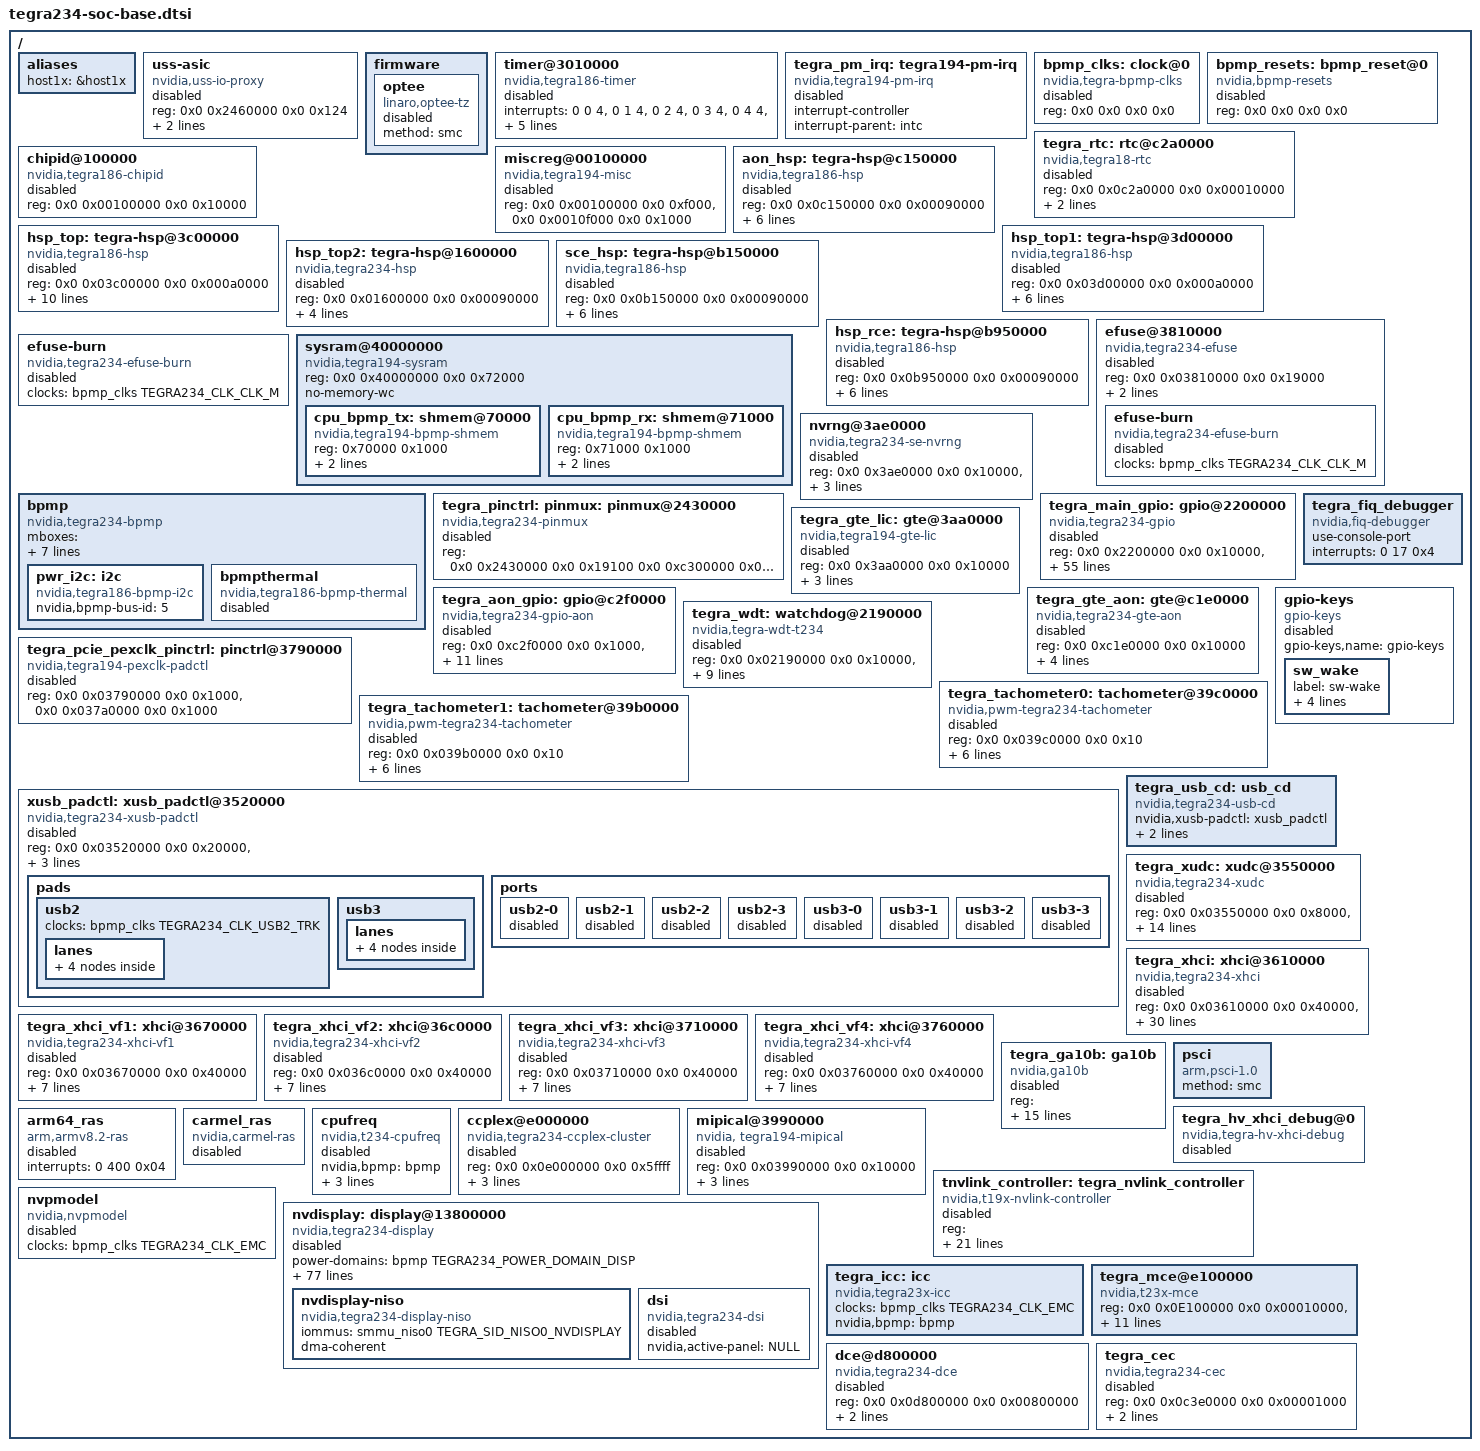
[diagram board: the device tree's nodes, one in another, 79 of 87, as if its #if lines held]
/*
 * Copyright (c) 2014-2023, NVIDIA CORPORATION.  All rights reserved.
 *
 * This program is free software; you can redistribute it and/or modify it
 * under the terms and conditions of the GNU General Public License,
 * version 2, as published by the Free Software Foundation.
 *
 * This program is distributed in the hope it will be useful, but WITHOUT
 * ANY WARRANTY; without even the implied warranty of MERCHANTABILITY or
 * FITNESS FOR A PARTICULAR PURPOSE.  See the GNU General Public License for
 * more details.
 *
 * You should have received a copy of the GNU General Public License
 * along with this program.  If not, see <http://www.gnu.org/licenses/>.
 */

/* FIXME: remove all the tegra194-*** headers */
#include <dt-bindings/version.h>
#include <dt-bindings/clock/tegra234-clock.h>
#include <dt-bindings/reset/tegra234-reset.h>
#include <dt-bindings/interrupt/tegra234-irq.h>
#include "dt-bindings/interrupt-controller/arm-gic.h"
#include "dt-bindings/soc/tegra234-powergate.h"
#include <dt-bindings/interrupt-controller/irq.h>
#include <dt-bindings/gpio/tegra234-gpio.h>
#include <dt-bindings/pinctrl/pinctrl-tegra.h>
#include <dt-bindings/mailbox/tegra186-hsp.h>
/* Minimal.dtsi is to be included first as subsequent headers can
 *override the nodes.
 */
#include "tegra234-soc/tegra234-soc-minimal.dtsi"
#include "tegra234-soc-memory.dtsi"
#include "tegra234-trusty.dtsi"
#include "tegra234-soc-cbb.dtsi"
#include "tegra234-soc-pcie.dtsi"
#include "tegra234-soc-eqos.dtsi"
#include "tegra234-soc-mgbe.dtsi"
#include "tegra234-soc-uart.dtsi"
#include "tegra234-soc-sdhci.dtsi"
#include "tegra234-soc-ufshc.dtsi"
#include "tegra234-soc-spi.dtsi"
#include "tegra234-soc-pwm.dtsi"
#include "tegra234-soc-i2c.dtsi"
#include "tegra234-soc-gpcdma.dtsi"
#include "tegra234-soc-can.dtsi"
#include "tegra234-soc-audio.dtsi"
#include "tegra234-safety-sce.dtsi"
#include "tegra234-camera.dtsi"
#include "tegra234-soc/tegra234-soc-actmon.dtsi"
#include "tegra234-soc/tegra234-aon.dtsi"
#include "tegra234-soc/tegra234-cpus.dtsi"
#include "tegra234-soc-thermal.dtsi"
#include "tegra234-soc-ldpc.dtsi"
#include "tegra234-soc/tegra234-psc.dtsi"
#include "dt-bindings/soc/tegra-io-pads.h"
#include "dt-bindings/input/input.h"
#include "tegra234-soc-pmc.dtsi"
#include "tegra234-soc-host1x.dtsi"
#include "tegra234-soc-mods.dtsi"
#include <dt-bindings/interconnect/tegra_icc_id.h>

#include "tegra234-soc/tegra234-automotive-nvguard.dtsi"
#include "tegra234-soc/tegra234-automotive-nvguard-srvprop.dtsi"

#include "tegra234-soc-coresight.dtsi"
#include "tegra234-soc-fsicom.dtsi"
#include "tegra234-safetyservice.dtsi"

/ {
	aliases {
		host1x = &host1x;
	};

	uss-asic {
		compatible = "nvidia,uss-io-proxy";
		reg = <0x0 0x2460000 0x0 0x124>;
		clocks = <&bpmp_clks TEGRA234_CLK_I2S8>;
		clock-names = "i2s8";
		resets = <&bpmp_resets TEGRA234_RESET_I2S8>;
		reset-names = "i2s8";
		status = "disabled";
	};

	firmware {
		optee {
			compatible = "linaro,optee-tz";
			method = "smc";
			status = "disabled";
		};
	};

	timer@3010000 {
		/* Do not enable this node (SOC Timer) as ARM Generic Timer
		 * (DT node="timer") should be used instead
		 */
		compatible = "nvidia,tegra186-timer";
		interrupts = <0 0 4>,
			     <0 1 4>,
			     <0 2 4>,
			     <0 3 4>,
			     <0 4 4>,
			     <0 5 4>,
			     <0 6 4>,
			     <0 7 4>;
		clock-frequency = <19200000>;
		reg = <0x0 0x03010000 0x0 0x000e0000>;
		tmr-count = <10>;
		wdt-count = <3>;
		status = "disabled";
	};

	tegra_pm_irq: tegra194-pm-irq {
		compatible = "nvidia,tegra194-pm-irq";
		interrupt-controller;
		#interrupt-cells = <3>;
		interrupt-parent = <&intc>;
		status = "disabled";
	};

#if TEGRA_BPMP_FW_DT_VERSION <= DT_VERSION_1
	bpmp_clks: clock@0 {
		compatible = "nvidia,tegra-bpmp-clks";
		reg = <0x0 0x0 0x0 0x0>;
		#clock-cells = <1>;
		status = "disabled";
	};

	bpmp_resets: bpmp_reset@0 {
		compatible = "nvidia,bpmp-resets";
		reg = <0x0 0x0 0x0 0x0>;
		#reset-cells = <1>;
		status = "disabled";
	};
#endif

	tegra_rtc: rtc@c2a0000 {
		compatible = "nvidia,tegra18-rtc";
		reg = <0x0 0x0c2a0000 0x0 0x00010000>;
		interrupt-parent = <&tegra_pmc>;
		interrupts = <73 IRQ_TYPE_LEVEL_HIGH>;
		status = "disabled";
	};

	chipid@100000 {
		compatible = "nvidia,tegra186-chipid";
		reg = <0x0 0x00100000 0x0 0x10000>;
		status = "disabled";
	};

	miscreg@00100000 {
		compatible = "nvidia,tegra194-misc", "nvidia,tegra186-miscreg";
		reg = <0x0 0x00100000 0x0 0xf000>, /* Chipid */
		    <0x0 0x0010f000 0x0 0x1000>; /* Straps */
		status = "disabled";
	};

	aon_hsp: tegra-hsp@c150000 {
		compatible = "nvidia,tegra186-hsp";
		reg = <0x0 0x0c150000 0x0 0x00090000>;
		interrupts =	<0 TEGRA234_IRQ_AON_HSP_SHARED_1 0x4>,
				<0 TEGRA234_IRQ_AON_HSP_SHARED_2 0x4>,
				<0 TEGRA234_IRQ_AON_HSP_SHARED_3 0x4>,
				<0 TEGRA234_IRQ_AON_HSP_SHARED_4 0x4>;
		interrupt-names = "shared1", "shared2", "shared3", "shared4";
		#mbox-cells = <2>;
		nvidia,mbox-ie;
		status = "disabled";
	};

	hsp_top: tegra-hsp@3c00000 {
		compatible = "nvidia,tegra186-hsp";
		reg = <0x0 0x03c00000 0x0 0x000a0000>;
		interrupts =	<0 176 0x4>,
				<0 TEGRA234_IRQ_TOP0_HSP_SHARED_0 0x4>,
				<0 TEGRA234_IRQ_TOP0_HSP_SHARED_1 0x4>,
				<0 TEGRA234_IRQ_TOP0_HSP_SHARED_2 0x4>,
				<0 TEGRA234_IRQ_TOP0_HSP_SHARED_3 0x4>,
				<0 TEGRA234_IRQ_TOP0_HSP_SHARED_4 0x4>,
				<0 TEGRA234_IRQ_TOP0_HSP_SHARED_5 0x4>,
				<0 TEGRA234_IRQ_TOP0_HSP_SHARED_6 0x4>,
				<0 TEGRA234_IRQ_TOP0_HSP_SHARED_7 0x4>;
		interrupt-names = "doorbell",
				"shared0", "shared1", "shared2", "shared3",
				"shared4", "shared5", "shared6", "shared7";
		#mbox-cells = <2>;
		nvidia,mbox-ie;
		status = "disabled";
	};

	hsp_top1: tegra-hsp@3d00000 {
		compatible = "nvidia,tegra186-hsp";
		reg = <0x0 0x03d00000 0x0 0x000a0000>;
		interrupts = <0 TEGRA234_IRQ_TOP1_HSP_SHARED_0 0x4>,
				<0 TEGRA234_IRQ_TOP1_HSP_SHARED_1 0x4>,
				<0 TEGRA234_IRQ_TOP1_HSP_SHARED_2 0x4>,
				<0 TEGRA234_IRQ_TOP1_HSP_SHARED_3 0x4>,
				<0 TEGRA234_IRQ_TOP1_HSP_SHARED_4 0x4>;
		interrupt-names = "shared0", "shared1", "shared2", "shared3", "shared4";
		#mbox-cells = <2>;
		status = "disabled";
	};

	hsp_top2: tegra-hsp@1600000 {
		compatible = "nvidia,tegra234-hsp","nvidia,tegra186-hsp";
		reg = <0x0 0x01600000 0x0 0x00090000>;
		interrupts = <0 265 0x4>, <0 266 0x4>, <0 267 0x4>,
        <0 268 0x4>, <0 269 0x4>, <0 270 0x4>, <0 271 0x4>, <0 272 0x4>;
		interrupt-names = "shared0", "shared1", "shared2", "shared3",
				"shared4", "shared5", "shared6", "shared7";
		#mbox-cells = <2>;
		nvidia,mbox-ie;
		status = "disabled";
	};




	sce_hsp: tegra-hsp@b150000 {
		compatible = "nvidia,tegra186-hsp";
		reg = <0x0 0x0b150000 0x0 0x00090000>;
		interrupts =	<0 TEGRA234_IRQ_SCE_HSP_SHARED_1 0x4>,
				<0 TEGRA234_IRQ_SCE_HSP_SHARED_2 0x4>,
				<0 TEGRA234_IRQ_SCE_HSP_SHARED_3 0x4>,
				<0 TEGRA234_IRQ_SCE_HSP_SHARED_4 0x4>;
		interrupt-names = "shared1", "shared2", "shared3", "shared4";
		nvidia,mbox-ie;
		status = "disabled";
	};

	hsp_rce: tegra-hsp@b950000 {
		compatible = "nvidia,tegra186-hsp";
		reg = <0x0 0x0b950000 0x0 0x00090000>;
		interrupts =	<0 TEGRA234_IRQ_RCE_HSP_SHARED_1 0x4>,
				<0 TEGRA234_IRQ_RCE_HSP_SHARED_2 0x4>,
				<0 TEGRA234_IRQ_RCE_HSP_SHARED_3 0x4>,
				<0 TEGRA234_IRQ_RCE_HSP_SHARED_4 0x4>;
		nvidia,mbox-ie;
		#mbox-cells = <2>;
		interrupt-names = "shared1", "shared2", "shared3", "shared4";
		status = "disabled";
	};

	efuse@3810000 {
		compatible = "nvidia,tegra234-efuse";
		reg = <0x0 0x03810000 0x0 0x19000>;
		clocks = <&bpmp_clks TEGRA234_CLK_FUSE>,
		         <&bpmp_clks TEGRA234_CLK_CLK_M>;
		clock-names = "fuse", "clk_m";
		status = "disabled";
#if LINUX_VERSION < 419
		efuse-burn {
			compatible = "nvidia,tegra234-efuse-burn";
			clocks = <&bpmp_clks TEGRA234_CLK_CLK_M>;
			clock-names = "clk_m";
			status = "disabled";
		};
#endif
	};

#if LINUX_VERSION >= 419
	efuse-burn {
		compatible = "nvidia,tegra234-efuse-burn";
		clocks = <&bpmp_clks TEGRA234_CLK_CLK_M>;
		clock-names = "clk_m";
		status = "disabled";
	};
#endif

#if TEGRA_BPMP_FW_DT_VERSION >= DT_VERSION_2
	sysram@40000000 {
		compatible = "nvidia,tegra194-sysram", "mmio-sram";
		reg = <0x0 0x40000000 0x0 0x72000>;
		#address-cells = <1>;
		#size-cells = <1>;
		ranges = <0x0 0x0 0x40000000 0x72000>;
		no-memory-wc;

		cpu_bpmp_tx: shmem@70000 {
			compatible = "nvidia,tegra194-bpmp-shmem";
			reg = <0x70000 0x1000>;
			label = "cpu-bpmp-tx";
			pool;
		};

		cpu_bpmp_rx: shmem@71000 {
			compatible = "nvidia,tegra194-bpmp-shmem";
			reg = <0x71000 0x1000>;
			label = "cpu-bpmp-rx";
			pool;
		};
	};

	bpmp: bpmp {
		compatible = "nvidia,tegra234-bpmp", "nvidia,tegra186-bpmp";
		mboxes = <&hsp_top TEGRA_HSP_MBOX_TYPE_DB
				   TEGRA_HSP_DB_MASTER_BPMP>;
		shmem = <&cpu_bpmp_tx &cpu_bpmp_rx>;
		#clock-cells = <1>;
		#reset-cells = <1>;
		#power-domain-cells = <1>;
#if TEGRA_IOMMU_DT_VERSION >= DT_VERSION_2
		interconnects = <&mc TEGRA234_MEMORY_CLIENT_BPMPR>,
				<&mc TEGRA234_MEMORY_CLIENT_BPMPW>,
				<&mc TEGRA234_MEMORY_CLIENT_BPMPDMAR>,
				<&mc TEGRA234_MEMORY_CLIENT_BPMPDMAW>;
		interconnect-names = "dma-mem", "dma-mem", "dma-mem", "dma-mem";
#endif

		pwr_i2c: i2c {
			compatible = "nvidia,tegra186-bpmp-i2c";
			nvidia,bpmp-bus-id = <5>;
			#address-cells = <1>;
			#size-cells = <0>;
		};

		bpmpthermal {
			compatible = "nvidia,tegra186-bpmp-thermal";
			#thermal-sensor-cells = <1>;
			status = "disabled";
		};
	};
#else
	bpmp: bpmp {
		compatible = "nvidia,tegra186-bpmp";
		iommus = <&smmu_niso1 TEGRA_SID_NISO1_BPMP>;
		dma-coherent;
		reg = <0x0 0x0d000000 0x0 0x00800000>,
		      <0x0 0x40070000 0x0 0x00001000>,
		      <0x0 0x40071000 0x0 0x00001000>;
		status = "disabled";
		#power-domain-cells = <1>;
		#strap-cells = <1>;
		#nvidia,controller-id-cells = <1>;

		bpmpthermal {
			compatible = "nvidia,tegra186-bpmp-thermal";
			#thermal-sensor-cells = <1>;
			status = "disabled";
		};
	};
#endif

	nvrng@3ae0000 {
		compatible = "nvidia,tegra234-se-nvrng";
		reg-names = "rng1", "sap";
		reg = <0x0 0x3ae0000 0x0 0x10000>,
		      <0x0 0x3ac0000 0x0 0x10000>;
		interrupts = <0x0 284 0x4>;
		clocks = <&bpmp_clks TEGRA234_CLK_SE>;
		clock-names = "se";
		status = "disabled";
	};

	tegra_pinctrl: pinmux: pinmux@2430000 {
		compatible = "nvidia,tegra234-pinmux";
		reg = <0x0 0x2430000 0x0 0x19100
			0x0 0xc300000 0x0 0x4000>;
		#gpio-range-cells = <3>;
		status = "disabled";
};

	tegra_main_gpio: gpio@2200000 {
		compatible = "nvidia,tegra234-gpio";
		reg-names = "security", "gpio";
		reg =
			<0x0 0x2200000 0x0 0x10000>,
			<0x0 0x2210000 0x0 0x10000>;
		interrupts =
			<0 TEGRA234_IRQ_GPIO0_0 IRQ_TYPE_LEVEL_HIGH>,
			<0 TEGRA234_IRQ_GPIO0_1 IRQ_TYPE_LEVEL_HIGH>,
			<0 TEGRA234_IRQ_GPIO0_2 IRQ_TYPE_LEVEL_HIGH>,
			<0 TEGRA234_IRQ_GPIO0_3 IRQ_TYPE_LEVEL_HIGH>,
			<0 TEGRA234_IRQ_GPIO0_4 IRQ_TYPE_LEVEL_HIGH>,
			<0 TEGRA234_IRQ_GPIO0_5 IRQ_TYPE_LEVEL_HIGH>,
			<0 TEGRA234_IRQ_GPIO0_6 IRQ_TYPE_LEVEL_HIGH>,
			<0 TEGRA234_IRQ_GPIO0_7 IRQ_TYPE_LEVEL_HIGH>,
			<0 TEGRA234_IRQ_GPIO1_0 IRQ_TYPE_LEVEL_HIGH>,
			<0 TEGRA234_IRQ_GPIO1_1 IRQ_TYPE_LEVEL_HIGH>,
			<0 TEGRA234_IRQ_GPIO1_2 IRQ_TYPE_LEVEL_HIGH>,
			<0 TEGRA234_IRQ_GPIO1_3 IRQ_TYPE_LEVEL_HIGH>,
			<0 TEGRA234_IRQ_GPIO1_4 IRQ_TYPE_LEVEL_HIGH>,
			<0 TEGRA234_IRQ_GPIO1_5 IRQ_TYPE_LEVEL_HIGH>,
			<0 TEGRA234_IRQ_GPIO1_6 IRQ_TYPE_LEVEL_HIGH>,
			<0 TEGRA234_IRQ_GPIO1_7 IRQ_TYPE_LEVEL_HIGH>,
			<0 TEGRA234_IRQ_GPIO2_0 IRQ_TYPE_LEVEL_HIGH>,
			<0 TEGRA234_IRQ_GPIO2_1 IRQ_TYPE_LEVEL_HIGH>,
			<0 TEGRA234_IRQ_GPIO2_2 IRQ_TYPE_LEVEL_HIGH>,
			<0 TEGRA234_IRQ_GPIO2_3 IRQ_TYPE_LEVEL_HIGH>,
			<0 TEGRA234_IRQ_GPIO2_4 IRQ_TYPE_LEVEL_HIGH>,
			<0 TEGRA234_IRQ_GPIO2_5 IRQ_TYPE_LEVEL_HIGH>,
			<0 TEGRA234_IRQ_GPIO2_6 IRQ_TYPE_LEVEL_HIGH>,
			<0 TEGRA234_IRQ_GPIO2_7 IRQ_TYPE_LEVEL_HIGH>,
			<0 TEGRA234_IRQ_GPIO3_0 IRQ_TYPE_LEVEL_HIGH>,
			<0 TEGRA234_IRQ_GPIO3_1 IRQ_TYPE_LEVEL_HIGH>,
			<0 TEGRA234_IRQ_GPIO3_2 IRQ_TYPE_LEVEL_HIGH>,
			<0 TEGRA234_IRQ_GPIO3_3 IRQ_TYPE_LEVEL_HIGH>,
			<0 TEGRA234_IRQ_GPIO3_4 IRQ_TYPE_LEVEL_HIGH>,
			<0 TEGRA234_IRQ_GPIO3_5 IRQ_TYPE_LEVEL_HIGH>,
			<0 TEGRA234_IRQ_GPIO3_6 IRQ_TYPE_LEVEL_HIGH>,
			<0 TEGRA234_IRQ_GPIO3_7 IRQ_TYPE_LEVEL_HIGH>,
			<0 TEGRA234_IRQ_GPIO4_0 IRQ_TYPE_LEVEL_HIGH>,
			<0 TEGRA234_IRQ_GPIO4_1 IRQ_TYPE_LEVEL_HIGH>,
			<0 TEGRA234_IRQ_GPIO4_2 IRQ_TYPE_LEVEL_HIGH>,
			<0 TEGRA234_IRQ_GPIO4_3 IRQ_TYPE_LEVEL_HIGH>,
			<0 TEGRA234_IRQ_GPIO4_4 IRQ_TYPE_LEVEL_HIGH>,
			<0 TEGRA234_IRQ_GPIO4_5 IRQ_TYPE_LEVEL_HIGH>,
			<0 TEGRA234_IRQ_GPIO4_6 IRQ_TYPE_LEVEL_HIGH>,
			<0 TEGRA234_IRQ_GPIO4_7 IRQ_TYPE_LEVEL_HIGH>,
			<0 TEGRA234_IRQ_GPIO5_0 IRQ_TYPE_LEVEL_HIGH>,
			<0 TEGRA234_IRQ_GPIO5_1 IRQ_TYPE_LEVEL_HIGH>,
			<0 TEGRA234_IRQ_GPIO5_2 IRQ_TYPE_LEVEL_HIGH>,
			<0 TEGRA234_IRQ_GPIO5_3 IRQ_TYPE_LEVEL_HIGH>,
			<0 TEGRA234_IRQ_GPIO5_4 IRQ_TYPE_LEVEL_HIGH>,
			<0 TEGRA234_IRQ_GPIO5_5 IRQ_TYPE_LEVEL_HIGH>,
			<0 TEGRA234_IRQ_GPIO5_6 IRQ_TYPE_LEVEL_HIGH>,
			<0 TEGRA234_IRQ_GPIO5_7 IRQ_TYPE_LEVEL_HIGH>;
		gpio-controller;
		#gpio-cells = <2>;
		interrupt-controller;
		#interrupt-cells = <2>;
		gpio-ranges =
			<&tegra_pinctrl TEGRA234_MAIN_GPIO_OFFSET TEGRA234_MAIN_PINCTRL_OFFSET_A TEGRA234_MAIN_PINS_A_TO_Z>,
			<&tegra_pinctrl TEGRA234_MAIN_PINS_A_TO_Z TEGRA234_MAIN_PINCTRL_OFFSET_AC TEGRA234_MAIN_PINS_AC_TO_AG>;
		status = "disabled";
	};

	tegra_aon_gpio: gpio@c2f0000 {
		compatible = "nvidia,tegra234-gpio-aon";
		reg-names = "security", "gpio";
		reg = 	<0x0 0xc2f0000 0x0 0x1000>,
			<0x0 0xc2f1000 0x0 0x1000>;
		interrupts =
			<0 TEGRA234_IRQ_AON_GPIO_0 IRQ_TYPE_LEVEL_HIGH>,
			<0 TEGRA234_IRQ_AON_GPIO_1 IRQ_TYPE_LEVEL_HIGH>,
			<0 TEGRA234_IRQ_AON_GPIO_2 IRQ_TYPE_LEVEL_HIGH>,
			<0 TEGRA234_IRQ_AON_GPIO_3 IRQ_TYPE_LEVEL_HIGH>;
		gpio-controller;
		#gpio-cells = <2>;
		interrupt-controller;
		#interrupt-cells = <2>;
		gpio-ranges =
			<&tegra_pinctrl TEGRA234_MAIN_GPIO_OFFSET TEGRA234_MAIN_PINS_A_TO_Z TEGRA234_AON_PINS_AA>,
			<&tegra_pinctrl TEGRA234_AON_PINS_AA TEGRA234_AON_PINCTRL_OFFSET_BB TEGRA234_AON_PINS_BB_TO_GG>;
		status = "disabled";
	};

	tegra_gte_lic: gte@3aa0000 {
                compatible = "nvidia,tegra194-gte-lic";
                reg = <0x0 0x3aa0000 0x0 0x10000>;
                interrupts = <0 11 0x4>;
                nvidia,int-threshold = <1>;
                nvidia,num-slices = <17>;
                status = "disabled";
        };

        tegra_gte_aon: gte@c1e0000 {
                compatible = "nvidia,tegra234-gte-aon";
                reg = <0x0 0xc1e0000 0x0 0x10000>;
                interrupts = <0 13 0x4>;
                nvidia,int-threshold = <1>;
                nvidia,num-slices = <3>;
                nvidia,gpio-controller = <&tegra_aon_gpio>;
                status = "disabled";
        };

	tegra_wdt: watchdog@2190000 {
		compatible = "nvidia,tegra-wdt-t234";
		reg = <0x0 0x02190000 0x0 0x10000>, /* WDT0 */
		      <0x0 0x02090000 0x0 0x10000>, /* TMR0 */
		      <0x0 0x02080000 0x0 0x10000>; /* TKE */
		interrupts = <0 7 0x4 0 8 0x4>; /* TKE shared int */
		nvidia,watchdog-index = <0>;
		nvidia,timer-index = <7>;
		nvidia,enable-on-init;
		nvidia,extend-watchdog-suspend;
		timeout-sec = <120>;
		nvidia,disable-debug-reset;
		status = "disabled";
	};

	tegra_fiq_debugger {
		compatible = "nvidia,fiq-debugger";
		use-console-port;
		interrupts = <0 17 0x4>;
	};

	tegra_pcie_pexclk_pinctrl: pinctrl@3790000 {
		compatible = "nvidia,tegra194-pexclk-padctl";
		reg = <0x0 0x03790000 0x0 0x1000>,
		      <0x0 0x037a0000 0x0 0x1000>;
		status = "disabled";
	};

	tegra_tachometer0: tachometer@39c0000 {
		compatible = "nvidia,pwm-tegra234-tachometer";
		reg = <0x0 0x039c0000 0x0 0x10>;
		#pwm-cells = <2>;
		clocks = <&bpmp_clks TEGRA234_CLK_TACH0>;
		clock-names = "tach";
		resets = <&bpmp_resets TEGRA234_RESET_TACH0>;
		reset-names = "tach";
		interrupts = <0 TEGRA234_IRQ_TACH0 0x4>;
		pulse-per-rev = <2>;
		capture-window-length = <2>;
		disable-clk-gate;
		status = "disabled";
	};

	tegra_tachometer1: tachometer@39b0000 {
		compatible = "nvidia,pwm-tegra234-tachometer";
		reg = <0x0 0x039b0000 0x0 0x10>;
		#pwm-cells = <2>;
		clocks = <&bpmp_clks TEGRA234_CLK_TACH1>;
		clock-names = "tach";
		resets = <&bpmp_resets TEGRA234_RESET_TACH1>;
		reset-names = "tach";
		interrupts = <0 TEGRA234_IRQ_TACH1 0x4>;
		pulse-per-rev = <2>;
		capture-window-length = <2>;
		disable-clk-gate;
		status = "disabled";
	};

	gpio-keys {
		compatible = "gpio-keys";
		gpio-keys,name = "gpio-keys";
		status = "disabled";

		sw_wake {
			label = "sw-wake";
			linux,code = <KEY_WAKEUP>;
			wakeup-source;
			interrupt-parent = <&tegra_pmc>;
			interrupts = <83 IRQ_TYPE_EDGE_RISING>;
		};
	};

	xusb_padctl: xusb_padctl@3520000 {
		compatible = "nvidia,tegra234-xusb-padctl";
		reg = <0x0 0x03520000 0x0 0x20000>,
			<0x0 0x03540000 0x0 0x10000>;
		reg-names = "padctl", "ao";
		interrupts = <0 167 0x4>;
		resets = <&bpmp_resets TEGRA234_RESET_XUSB_PADCTL>;
		reset-names = "padctl";
		status = "disabled";

		pads {
			usb2 {
				clocks = <&bpmp_clks TEGRA234_CLK_USB2_TRK>;
				clock-names = "trk";

				lanes {
					usb2-0 {
						status = "disabled";
						#phy-cells = <0>;
					};
					usb2-1 {
						status = "disabled";
						#phy-cells = <0>;
					};
					usb2-2 {
						status = "disabled";
						#phy-cells = <0>;
					};
					usb2-3 {
						status = "disabled";
						#phy-cells = <0>;
					};
				};
			};
			usb3 {
				lanes {
					usb3-0 {
						status = "disabled";
						#phy-cells = <0>;
					};
					usb3-1 {
						status = "disabled";
						#phy-cells = <0>;
					};
					usb3-2 {
						status = "disabled";
						#phy-cells = <0>;
					};
					usb3-3 {
						status = "disabled";
						#phy-cells = <0>;
					};
				};
			};
		};

		ports {
			usb2-0 {
				status = "disabled";
			};
			usb2-1 {
				status = "disabled";
			};
			usb2-2 {
				status = "disabled";
			};
			usb2-3 {
				status = "disabled";
			};
			usb3-0 {
				status = "disabled";
			};
			usb3-1 {
				status = "disabled";
			};
			usb3-2 {
				status = "disabled";
			};
			usb3-3 {
				status = "disabled";
			};
		};
	};

	tegra_usb_cd: usb_cd {
		compatible = "nvidia,tegra234-usb-cd";
		nvidia,xusb-padctl = <&xusb_padctl>;
		phys = <&{/xusb_padctl@3520000/pads/usb2/lanes/usb2-0}>;
		phy-names = "otg-phy";
		status = "okay";
	};

	tegra_xudc: xudc@3550000 {
		compatible = "nvidia,tegra234-xudc";
		reg = <0x0 0x03550000 0x0 0x8000>,
			<0x0 0x03558000 0x0 0x8000>;
		reg-names = "base", "fpci";
		interrupts = <0 166 0x4>;
		clocks = <&bpmp_clks TEGRA234_CLK_XUSB_CORE_DEV>,
			<&bpmp_clks TEGRA234_CLK_XUSB_SS_SUPERSPEED>,
			<&bpmp_clks TEGRA234_CLK_XUSB_SS>,
			<&bpmp_clks TEGRA234_CLK_XUSB_FS>;
		clock-names = "dev", "ss", "ss_src", "fs_src";

#if defined(LINUX_VERSION) && LINUX_VERSION > 414
                power-domains =  <&bpmp TEGRA234_POWER_DOMAIN_XUSBB>,
                        <&bpmp TEGRA234_POWER_DOMAIN_XUSBA>,
                        <&bpmp TEGRA234_POWER_DOMAIN_XUSBC>;
                power-domain-names = "dev", "ss", "host";
#endif

		nvidia,xusb-padctl = <&xusb_padctl>;

		iommus = <&smmu_niso1 TEGRA_SID_NISO1_XUSB_DEV>;
		dma-coherent;

		status = "disabled";
		charger-detector = <&tegra_usb_cd>;
	};

	tegra_xhci: xhci@3610000 {
		compatible = "nvidia,tegra234-xhci", "nvidia,tegra234-xusb";
		reg = <0x0 0x03610000 0x0 0x40000>,
			<0x0 0x03600000 0x0 0x10000>,
			<0x0 0x03650000 0x0 0x10000>;
		reg-names = "base", "fpci", "bar2";
		interrupts-extended = <&intc 0 163 0x4>,
				      <&intc 0 164 0x4>,
				      <&intc 0 167 0x4>,
				      <&tegra_pmc 76 0x4>,
				      <&tegra_pmc 77 0x4>,
				      <&tegra_pmc 78 0x4>,
				      <&tegra_pmc 79 0x4>,
				      <&tegra_pmc 80 0x4>,
				      <&tegra_pmc 81 0x4>,
				      <&tegra_pmc 82 0x4>;
		/*
                   wake0, wake1, wake2 are for USB3.0 ports
                   wake3, wake4, wake5, wake6 are for USB2.0 ports
		*/
		interrupt-names = "xhci", "mbox", "padctl",
				  "wake0", "wake1", "wake2", "wake3",
				  "wake4", "wake5", "wake6";

		clocks = <&bpmp_clks TEGRA234_CLK_XUSB_CORE_MUX>,
			<&bpmp_clks TEGRA234_CLK_XUSB_CORE_HOST>,
			<&bpmp_clks TEGRA234_CLK_XUSB_CORE_SS>,
			<&bpmp_clks TEGRA234_CLK_XUSB_FALCON>,
			<&bpmp_clks TEGRA234_CLK_XUSB_FALCON_HOST>,
			<&bpmp_clks TEGRA234_CLK_XUSB_FALCON_SS>,
			<&bpmp_clks TEGRA234_CLK_XUSB_FS>,
			<&bpmp_clks TEGRA234_CLK_XUSB_FS_HOST>,
			<&bpmp_clks TEGRA234_CLK_XUSB_SS>,
			<&bpmp_clks TEGRA234_CLK_XUSB_SS_SUPERSPEED>,
			<&bpmp_clks TEGRA234_CLK_UTMIP_PLL>,
			<&bpmp_clks TEGRA234_CLK_CLK_M>,
			<&bpmp_clks TEGRA234_CLK_PLLE>;
		clock-names = "xusb_hs_src", "xusb_host",
			"xusb_core_superspeed_clk", "xusb_falcon_src",
			"xusb_falcon_host_clk", "xusb_falcon_superspeed_clk",
			"xusb_fs_src", "xusb_fs_host_clk", "xusb_ss_src",
			"xusb_ss", "pll_u_480m", "clk_m", "pll_e";

#if defined(LINUX_VERSION) && LINUX_VERSION > 414
		power-domains =  <&bpmp TEGRA234_POWER_DOMAIN_XUSBC>,
			<&bpmp TEGRA234_POWER_DOMAIN_XUSBA>;
		power-domain-names = "xusb_host", "xusb_ss";
#endif

		nvidia,xusb-padctl = <&xusb_padctl>;

#if TEGRA_IOMMU_DT_VERSION >= DT_VERSION_2
		interconnects = <&mc TEGRA234_MEMORY_CLIENT_XUSB_HOSTR>,
				<&mc TEGRA234_MEMORY_CLIENT_XUSB_HOSTW>;
		interconnect-names = "dma-mem", "dma-mem";
#endif
		iommus = <&smmu_niso1 TEGRA_SID_NISO1_XUSB_HOST>;
		dma-coherent;

		status = "disabled";
	};

	tegra_xhci_vf1: xhci@3670000 {
		compatible = "nvidia,tegra234-xhci-vf1";
		reg = <0x0 0x03670000 0x0 0x40000>;
		interrupts = <0 21 0x4>;

		nvidia,xusb-padctl = <&xusb_padctl>;

#if TEGRA_IOMMU_DT_VERSION >= DT_VERSION_2
		interconnects = <&mc TEGRA234_MEMORY_CLIENT_XUSB_HOSTR>,
				<&mc TEGRA234_MEMORY_CLIENT_XUSB_HOSTW>;
		interconnect-names = "dma-mem", "dma-mem";
#endif
		iommus = <&smmu_niso1 TEGRA_SID_NISO1_XUSB_VF0>;
		dma-coherent;

		status = "disabled";
	};

	tegra_xhci_vf2: xhci@36c0000 {
		compatible = "nvidia,tegra234-xhci-vf2";
		reg = <0x0 0x036c0000 0x0 0x40000>;
		interrupts = <0 22 0x4>;

		nvidia,xusb-padctl = <&xusb_padctl>;

#if TEGRA_IOMMU_DT_VERSION >= DT_VERSION_2
		interconnects = <&mc TEGRA234_MEMORY_CLIENT_XUSB_HOSTR>,
				<&mc TEGRA234_MEMORY_CLIENT_XUSB_HOSTW>;
		interconnect-names = "dma-mem", "dma-mem";
#endif
		iommus = <&smmu_niso1 TEGRA_SID_NISO1_XUSB_VF1>;
		dma-coherent;

		status = "disabled";
	};

	tegra_xhci_vf3: xhci@3710000 {
		compatible = "nvidia,tegra234-xhci-vf3";
		reg = <0x0 0x03710000 0x0 0x40000>;
		interrupts = <0 23 0x4>;

		nvidia,xusb-padctl = <&xusb_padctl>;

#if TEGRA_IOMMU_DT_VERSION >= DT_VERSION_2
		interconnects = <&mc TEGRA234_MEMORY_CLIENT_XUSB_HOSTR>,
				<&mc TEGRA234_MEMORY_CLIENT_XUSB_HOSTW>;
		interconnect-names = "dma-mem", "dma-mem";
#endif
		iommus = <&smmu_niso1 TEGRA_SID_NISO1_XUSB_VF2>;
		dma-coherent;

		status = "disabled";
	};

	tegra_xhci_vf4: xhci@3760000 {
		compatible = "nvidia,tegra234-xhci-vf4";
		reg = <0x0 0x03760000 0x0 0x40000>;
		interrupts = <0 24 0x4>;

		nvidia,xusb-padctl = <&xusb_padctl>;

#if TEGRA_IOMMU_DT_VERSION >= DT_VERSION_2
		interconnects = <&mc TEGRA234_MEMORY_CLIENT_XUSB_HOSTR>,
				<&mc TEGRA234_MEMORY_CLIENT_XUSB_HOSTW>;
		interconnect-names = "dma-mem", "dma-mem";
#endif
		iommus = <&smmu_niso1 TEGRA_SID_NISO1_XUSB_VF3>;
		dma-coherent;

		status = "disabled";
	};

	tegra_ga10b: ga10b {
		compatible = "nvidia,ga10b";
		#cooling-cells = <2>;
		reg = <0x0 0x17000000 0x0 0x1000000
		       0x0 0x18000000 0x0 0x1000000
		       0x0 0x03b41000 0x0 0x00001000>;
		interrupts = <0 68 0x04
		              0 70 0x04
		              0 71 0x04
		              0 67 0x04>;
		dma-noncontig;
		interrupt-names = "stall0", "stall1", "stall2", "nonstall";
		nvidia,host1x = <&host1x>;
		access-vpr-phys;
		power-domains = <&bpmp TEGRA234_POWER_DOMAIN_GPU>;
		clocks = <&bpmp_clks TEGRA234_CLK_GPUSYS>,
			<&bpmp_clks TEGRA234_CLK_GPC0CLK>,
			<&bpmp_clks TEGRA234_CLK_GPC1CLK>,
			<&bpmp_clks TEGRA234_CLK_FUSE>;
		clock-names = "sysclk", "gpc0clk", "gpc1clk", "fuse";
		resets = <&bpmp_resets TEGRA234_RESET_GPU>;
		dma-coherent;
		nvidia,bpmp = <&bpmp>;
		support-gpu-tools = <1>;
		status = "disabled";
	};

	psci {
		compatible = "arm,psci-1.0";
		method = "smc";
		status = "okay";
	};

	tegra_hv_xhci_debug@0 {
		compatible = "nvidia,tegra-hv-xhci-debug";
		status = "disabled";
	};

	arm64_ras: arm64_ras {
		compatible = "arm,armv8.2-ras";
		interrupts = <0 400 0x04>;
		status = "disabled";
	};

	carmel_ras {
		compatible = "nvidia,carmel-ras";
		status = "disabled";
	};

	cpufreq {
		compatible = "nvidia,t234-cpufreq";
		nvidia,bpmp = <&bpmp>;
		reg = <0x0 0x0e000000 0x0 0x5ffff>; /* MMCRAB base */
		status = "disabled";
		cpu_emc_map = <1500000 800000>,
				<900000  665000>,
				<550000  533000>,
				<340000  204000>;
	};

	ccplex@e000000 {
		compatible = "nvidia,tegra234-ccplex-cluster";
		reg = <0x0 0x0e000000 0x0 0x5ffff>;
		nvidia,bpmp = <&bpmp>;
		status = "disabled";
		cpu_emc_map = <1500000 800000>,
				<900000  665000>,
				<550000  533000>,
				<340000  204000>;
	};

	mipical@3990000{
		compatible = "nvidia, tegra194-mipical";
		reg = <0x0 0x03990000 0x0 0x10000>;
		clocks = <&bpmp_clks TEGRA234_CLK_MIPI_CAL>,
			<&bpmp_clks TEGRA234_CLK_UART_FST_MIPI_CAL>;
		clock-names = "mipi_cal", "uart_fs_mipi_cal";
		resets = <&bpmp_resets TEGRA234_RESET_MIPI_CAL>;
		reset-names = "mipi_cal";
		status = "disabled";
	};

	tnvlink_controller: tegra_nvlink_controller {
		compatible = "nvidia,t19x-nvlink-controller";
		reg = <0x0 0x3b80000 0x0 0x1000 /* NVLW_TIOCTRL */
		       0x0 0x3b84000 0x0 0x1000 /* NVLW_NVLIPT */
		       0x0 0x3b86000 0x0 0x1000 /* NVLW_MINION */
		       0x0 0x3b90000 0x0 0x4000 /* NVLW_NVL */
		       0x0 0x3b94000 0x0 0x1000 /* NVLW_SYNC2X */
		       0x0 0x3b96000 0x0 0x1000 /* NVLW_NVLTLC */
		       0x0 0x1f00000 0x0 0x20000>; /* MSSNVLINK_0 */
		clocks = <&bpmp_clks TEGRA234_CLK_NVHS_PLL0_MGMT>,
				<&bpmp_clks TEGRA234_CLK_PLLREFE_VCOOUT_GATED>,
				<&bpmp_clks TEGRA234_CLK_OSC>,
				<&bpmp_clks TEGRA234_CLK_PLLNVHS>,
				<&bpmp_clks TEGRA234_CLK_CLK_M>,
				<&bpmp_clks TEGRA234_CLK_OSC>,
				<&bpmp_clks TEGRA234_CLK_OSC>;
		clock-names = "nvhs_pll0_mgmt", "pllrefe_vcoout_gated", "nvlink_sys", "pllnvhs", "clk_m", "nvlink_pll_txclk", "nvlink_tx";
		resets = <&bpmp_resets TEGRA234_RESET_NVHS_UPHY_PM>,
				<&bpmp_resets TEGRA234_RESET_NVHS_UPHY>,
				<&bpmp_resets TEGRA234_RESET_NVHS_UPHY_PLL0>,
				<&bpmp_resets TEGRA234_RESET_NVHS_UPHY_L0>,
				<&bpmp_resets TEGRA234_RESET_NVHS_UPHY_L1>,
				<&bpmp_resets TEGRA234_RESET_NVHS_UPHY_L2>,
				<&bpmp_resets TEGRA234_RESET_NVHS_UPHY_L3>,
				<&bpmp_resets TEGRA234_RESET_NVHS_UPHY_L4>,
				<&bpmp_resets TEGRA234_RESET_NVHS_UPHY_L5>,
				<&bpmp_resets TEGRA234_RESET_NVHS_UPHY_L6>,
				<&bpmp_resets TEGRA234_RESET_NVHS_UPHY_L7>;
		reset-names = "nvhs_uphy_pm", "nvhs_uphy", "nvhs_uphy_pll0",
				"nvhs_uphy_l0", "nvhs_uphy_l1", "nvhs_uphy_l2",
				"nvhs_uphy_l3",	"nvhs_uphy_l4",	"nvhs_uphy_l5",
				"nvhs_uphy_l6",	"nvhs_uphy_l7";
		interrupts = <0 178 0x4>; /* NVLINK2HOST interrupt */
		status = "disabled";
	};

	nvpmodel {
		compatible = "nvidia,nvpmodel";
		clocks = <&bpmp_clks TEGRA234_CLK_EMC>;
		clock-names = "emc";
		status = "disabled";
	};

	nvdisplay: display@13800000 {
		compatible = "nvidia,tegra234-display";
		power-domains = <&bpmp TEGRA234_POWER_DOMAIN_DISP>;
		nvidia,num-dpaux-instance = <1>;
		reg-names = "nvdisplay", "dpaux0", "hdacodec", "mipical";
		reg = <0x0 0x13800000 0x0 0xEFFFF    /* nvdisplay */
		       0x0 0x155C0000 0x0 0xFFFF     /* dpaux0 */
		       0x0 0x0242c000 0x0 0x1000     /* hdacodec */
		       0x0 0x03990000 0x0 0x10000>;  /* mipical */
		interrupt-names = "nvdisplay", "dpaux0", "hdacodec";
		interrupts = <0 416 4
		              0 419 4
			      0  61 4>;
		nvidia,bpmp = <&bpmp>;
		clocks = <&bpmp_clks TEGRA234_CLK_HUB>,
			 <&bpmp_clks TEGRA234_CLK_DISP>,
			 <&bpmp_clks TEGRA234_CLK_NVDISPLAY_P0>,
			 <&bpmp_clks TEGRA234_CLK_NVDISPLAY_P1>,
			 <&bpmp_clks TEGRA234_CLK_DPAUX>,
			 <&bpmp_clks TEGRA234_CLK_FUSE>,
			 <&bpmp_clks TEGRA234_CLK_DSIPLL_VCO>,
			 <&bpmp_clks TEGRA234_CLK_DSIPLL_CLKOUTPN>,
			 <&bpmp_clks TEGRA234_CLK_DSIPLL_CLKOUTA>,
			 <&bpmp_clks TEGRA234_CLK_SPPLL0_VCO>,
			 <&bpmp_clks TEGRA234_CLK_SPPLL0_CLKOUTPN>,
			 <&bpmp_clks TEGRA234_CLK_SPPLL0_CLKOUTA>,
			 <&bpmp_clks TEGRA234_CLK_SPPLL0_CLKOUTB>,
			 <&bpmp_clks TEGRA234_CLK_SPPLL0_DIV10>,
			 <&bpmp_clks TEGRA234_CLK_SPPLL0_DIV25>,
			 <&bpmp_clks TEGRA234_CLK_SPPLL0_DIV27PN>,
			 <&bpmp_clks TEGRA234_CLK_SPPLL1_VCO>,
			 <&bpmp_clks TEGRA234_CLK_SPPLL1_CLKOUTPN>,
			 <&bpmp_clks TEGRA234_CLK_SPPLL1_DIV27PN>,
			 <&bpmp_clks TEGRA234_CLK_VPLL0_REF>,
			 <&bpmp_clks TEGRA234_CLK_VPLL0>,
			 <&bpmp_clks TEGRA234_CLK_VPLL1>,
			 <&bpmp_clks TEGRA234_CLK_NVDISPLAY_P0_REF>,
			 <&bpmp_clks TEGRA234_CLK_RG0>,
			 <&bpmp_clks TEGRA234_CLK_RG1>,
			 <&bpmp_clks TEGRA234_CLK_DISPPLL>,
			 <&bpmp_clks TEGRA234_CLK_DISPHUBPLL>,
			 <&bpmp_clks TEGRA234_CLK_DSI_LP>,
			 <&bpmp_clks TEGRA234_CLK_DSI_CORE>,
			 <&bpmp_clks TEGRA234_CLK_DSI_PIXEL>,
			 <&bpmp_clks TEGRA234_CLK_PRE_SOR0>,
			 <&bpmp_clks TEGRA234_CLK_PRE_SOR1>,
			 <&bpmp_clks TEGRA234_CLK_DP_LINK_REF>,
			 <&bpmp_clks TEGRA234_CLK_SOR_LINKA_INPUT>,
			 <&bpmp_clks TEGRA234_CLK_SOR_LINKA_AFIFO>,
			 <&bpmp_clks TEGRA234_CLK_SOR_LINKA_AFIFO_M>,
			 <&bpmp_clks TEGRA234_CLK_RG0_M>,
			 <&bpmp_clks TEGRA234_CLK_RG1_M>,
			 <&bpmp_clks TEGRA234_CLK_SOR0_M>,
			 <&bpmp_clks TEGRA234_CLK_SOR1_M>,
			 <&bpmp_clks TEGRA234_CLK_PLLHUB>,
			 <&bpmp_clks TEGRA234_CLK_SOR0>,
			 <&bpmp_clks TEGRA234_CLK_SOR1>,
			 <&bpmp_clks TEGRA234_CLK_SOR_PAD_INPUT>,
			 <&bpmp_clks TEGRA234_CLK_PRE_SF0>,
			 <&bpmp_clks TEGRA234_CLK_SF0>,
			 <&bpmp_clks TEGRA234_CLK_SF1>,
			 <&bpmp_clks TEGRA234_CLK_DSI_PAD_INPUT>,
			 <&bpmp_clks TEGRA234_CLK_PRE_SOR0_REF>,
			 <&bpmp_clks TEGRA234_CLK_PRE_SOR1_REF>,
			 <&bpmp_clks TEGRA234_CLK_SOR0_PLL_REF>,
			 <&bpmp_clks TEGRA234_CLK_SOR1_PLL_REF>,
			 <&bpmp_clks TEGRA234_CLK_SOR0_REF>,
			 <&bpmp_clks TEGRA234_CLK_SOR1_REF>,
			 <&bpmp_clks TEGRA234_CLK_OSC>,
			 <&bpmp_clks TEGRA234_CLK_DSC>,
			 <&bpmp_clks TEGRA234_CLK_MAUD>,
			 <&bpmp_clks TEGRA234_CLK_AZA_2XBIT>,
			 <&bpmp_clks TEGRA234_CLK_AZA_BIT>,
			 <&bpmp_clks TEGRA234_CLK_MIPI_CAL>,
			 <&bpmp_clks TEGRA234_CLK_UART_FST_MIPI_CAL>,
			 <&bpmp_clks TEGRA234_CLK_SOR0_DIV>;
		clock-names = "nvdisplayhub_clk",
			      "nvdisplay_disp_clk",
			      "nvdisplay_p0_clk",
			      "nvdisplay_p1_clk",
			      "dpaux0_clk",
			      "fuse_clk",
			      "dsipll_vco_clk",
			      "dsipll_clkoutpn_clk",
			      "dsipll_clkouta_clk",
			      "sppll0_vco_clk",
			      "sppll0_clkoutpn_clk",
			      "sppll0_clkouta_clk",
			      "sppll0_clkoutb_clk",
			      "sppll0_div10_clk",
			      "sppll0_div25_clk",
			      "sppll0_div27_clk",
			      "sppll1_vco_clk",
			      "sppll1_clkoutpn_clk",
			      "sppll1_div27_clk",
			      "vpll0_ref_clk",
			      "vpll0_clk",
			      "vpll1_clk",
			      "nvdisplay_p0_ref_clk",
			      "rg0_clk",
			      "rg1_clk",
			      "disppll_clk",
			      "disphubpll_clk",
			      "dsi_lp_clk",
			      "dsi_core_clk",
			      "dsi_pixel_clk",
			      "pre_sor0_clk",
			      "pre_sor1_clk",
			      "dp_link_ref_clk",
			      "sor_linka_input_clk",
			      "sor_linka_afifo_clk",
			      "sor_linka_afifo_m_clk",
			      "rg0_m_clk",
			      "rg1_m_clk",
			      "sor0_m_clk",
			      "sor1_m_clk",
			      "pllhub_clk",
			      "sor0_clk",
			      "sor1_clk",
			      "sor_pad_input_clk",
			      "pre_sf0_clk",
			      "sf0_clk",
			      "sf1_clk",
			      "dsi_pad_input_clk",
			      "pre_sor0_ref_clk",
			      "pre_sor1_ref_clk",
			      "sor0_ref_pll_clk",
			      "sor1_ref_pll_clk",
			      "sor0_ref_clk",
			      "sor1_ref_clk",
			      "osc_clk",
			      "dsc_clk",
			      "maud_clk",
			      "aza_2xbit_clk",
			      "aza_bit_clk",
			      "mipi_cal_clk",
			      "uart_fst_mipi_cal_clk",
			      "sor0_div_clk";
		resets = <&bpmp_resets TEGRA234_RESET_NVDISPLAY>,
			 <&bpmp_resets TEGRA234_RESET_DPAUX>,
			 <&bpmp_resets TEGRA234_RESET_DSI_CORE>,
			 <&bpmp_resets TEGRA234_RESET_MIPI_CAL>;
		reset-names = "nvdisplay_reset",
			      "dpaux0_reset",
			      "dsi_core_reset",
			      "mipi_cal_reset";
		status = "disabled";
		nvidia,disp-sw-soc-chip-id = <0x2350>;
#if TEGRA_IOMMU_DT_VERSION >= DT_VERSION_2
		interconnects = <&mc TEGRA234_MEMORY_CLIENT_NVDISPLAYR>,
			        <&mc TEGRA234_MEMORY_CLIENT_NVDISPLAYR1>;
		interconnect-names = "dma-mem", "read-1";
#endif

		iommus = <&smmu_iso TEGRA_SID_ISO_NVDISPLAY>;
		non-coherent;
		nvdisplay-niso {
			compatible = "nvidia,tegra234-display-niso";
			iommus = <&smmu_niso0 TEGRA_SID_NISO0_NVDISPLAY>;
			dma-coherent;
		};
		dsi {
			compatible = "nvidia,tegra234-dsi";
			nvidia,active-panel = "NULL";
			status = "disabled";
		};
	};

	tegra_icc: icc {
		#interconnect-cells = <1>;
		clocks = <&bpmp_clks TEGRA234_CLK_EMC>;
		clock-names = "emc";
		compatible = "nvidia,tegra23x-icc";
		nvidia,bpmp = <&bpmp>;
		status = "okay";
	};

	tegra_mce@e100000 {
		compatible = "nvidia,t23x-mce";
		reg =   <0x0 0x0E100000 0x0 0x00010000>, /* ARI BASE Core 0*/
			<0x0 0x0E110000 0x0 0x00010000>,
			<0x0 0x0E120000 0x0 0x00010000>,
			<0x0 0x0E130000 0x0 0x00010000>,
			<0x0 0x0E140000 0x0 0x00010000>,
			<0x0 0x0E150000 0x0 0x00010000>,
			<0x0 0x0E160000 0x0 0x00010000>,
			<0x0 0x0E170000 0x0 0x00010000>,
			<0x0 0x0E180000 0x0 0x00010000>,
			<0x0 0x0E190000 0x0 0x00010000>,
			<0x0 0x0E1A0000 0x0 0x00010000>,
			<0x0 0x0E1B0000 0x0 0x00010000>;
		status = "okay";
	};

	dce@d800000 {
		compatible = "nvidia,tegra234-dce";
		reg = <0x0 0x0d800000 0x0 0x00800000>;
		interrupts =
			<0 376 0x4>,
			<0 377 0x4>;
		interrupt-names = "wdt-remote",
			"dce-sm0";
		iommus = <&smmu_niso0 TEGRA_SID_NISO0_DCE>;
		status = "disabled";
	};

	tegra_cec: tegra_cec {
		compatible = "nvidia,tegra234-cec";
		reg = <0x0 0x0c3e0000 0x0 0x00001000>;
		interrupts = <0 279 0x04>;
		resets = <&bpmp_resets TEGRA234_RESET_CEC>;
		reset-names = "cec";
		status = "disabled";
	};
};
